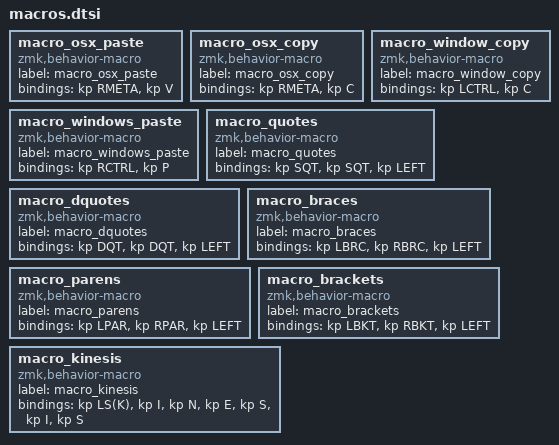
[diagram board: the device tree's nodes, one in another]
macro_osx_paste: macro_osx_paste{
compatible = "zmk,behavior-macro";
label = "macro_osx_paste";
#binding-cells = <0>;
bindings = <&kp RMETA>, <&kp V>;
};
macro_osx_copy: macro_osx_copy{
compatible = "zmk,behavior-macro";
label = "macro_osx_copy";
#binding-cells = <0>;
bindings = <&kp RMETA>, <&kp C>;
};
macro_windows_paste: macro_windows_paste{
compatible = "zmk,behavior-macro";
label = "macro_windows_paste";
#binding-cells = <0>;
bindings = <&kp RCTRL>, <&kp P>;
};
macro_window_copy: macro_window_copy{
compatible = "zmk,behavior-macro";
label = "macro_window_copy";
#binding-cells = <0>;
bindings = <&kp LCTRL>, <&kp C>;
};
macro_quotes: macro_quotes{
compatible = "zmk,behavior-macro";
label = "macro_quotes";
#binding-cells = <0>;
bindings = <&kp SQT>, <&kp SQT>, <&kp LEFT>;
};
macro_dquotes: macro_dquotes{
compatible = "zmk,behavior-macro";
label = "macro_dquotes";
#binding-cells = <0>;
bindings = <&kp DQT>, <&kp DQT>, <&kp LEFT>;
};
macro_braces: macro_braces{
compatible = "zmk,behavior-macro";
label = "macro_braces";
#binding-cells = <0>;
bindings = <&kp LBRC>, <&kp RBRC>, <&kp LEFT>;
};
macro_parens: macro_parens{
compatible = "zmk,behavior-macro";
label = "macro_parens";
#binding-cells = <0>;
bindings = <&kp LPAR>, <&kp RPAR>, <&kp LEFT>;
};
macro_brackets: macro_brackets{
compatible = "zmk,behavior-macro";
label = "macro_brackets";
#binding-cells = <0>;
bindings = <&kp LBKT>, <&kp RBKT>, <&kp LEFT>;
};
macro_kinesis: macro_kinesis{
compatible = "zmk,behavior-macro";
label = "macro_kinesis";
#binding-cells = <0>;
bindings = <&kp LS(K)>, <&kp I>, <&kp N>, <&kp E>, <&kp S>, <&kp I>, <&kp S>;
};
